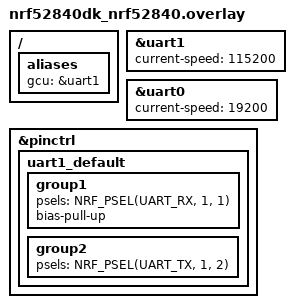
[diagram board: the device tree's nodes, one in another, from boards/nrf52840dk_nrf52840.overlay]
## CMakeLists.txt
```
# SPDX-License-Identifier: Apache-2.0

cmake_minimum_required(VERSION 3.20.0)
find_package(Zephyr REQUIRED HINTS $ENV{ZEPHYR_BASE})
project(prac2)

target_sources(app PRIVATE src/main.c)

zephyr_include_directories(../../include)

file(GLOB MYLIB_SOURCES ../../mylib/*.c)

foreach(mylib_src ${MYLIB_SOURCES})
    zephyr_library_sources(${mylib_src})
endforeach()
```

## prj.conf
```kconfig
CONFIG_GPIO=y
CONFIG_SERIAL=y
CONFIG_RING_BUFFER=y
CONFIG_PIPES=y
CONFIG_CBPRINTF_FP_SUPPORT=y
#CONFIG_PRINTK_BUFFER_SIZE=1 
#CONFIG_SHELL_STACK_SIZE=2048
CONFIG_UART_ASYNC_API=y

# get uart console on uart0 and async uart on uart1
CONFIG_UART_0_INTERRUPT_DRIVEN=n # Instance used by shell
CONFIG_UART_0_ASYNC=y
CONFIG_UART_0_NRF_HW_ASYNC=y
# enabling hw counting
CONFIG_UART_0_NRF_HW_ASYNC_TIMER=2
#CONFIG_UART_1_ASYNC=y
# instance for other purposes supporting async api
#CONFIG_UART_1_INTERRUPT_DRIVEN=n
#CONFIG_UART_1_NRF_HW_ASYNC=y
# enabling hw counting
#CONFIG_UART_1_NRF_HW_ASYNC_TIMER=2
# picking timer instance used for that

CONFIG_SYSTEM_WORKQUEUE_STACK_SIZE=2048

# Use the JSON library
CONFIG_JSON_LIBRARY=y


# RTT settings
CONFIG_SHELL_STACK_SIZE=1024
CONFIG_SHELL_BACKEND_SERIAL=n
CONFIG_SHELL_BACKEND_RTT=y
CONFIG_USE_SEGGER_RTT=y
```

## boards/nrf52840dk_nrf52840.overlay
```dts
/ {
    aliases {
        gcu = &uart1;
    };
};

&uart1 {
    status = "okay";
    current-speed = <115200>;
};

&uart0 {
    current-speed = <19200>;
};

&pinctrl {
	uart1_default: uart1_default {
		group1 {
			psels = <NRF_PSEL(UART_RX, 1, 1)>;
			bias-pull-up;
		};
		group2 {
			psels = <NRF_PSEL(UART_TX, 1, 2)>;
		};
	};
};
```

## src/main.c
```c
#include "async_uart.h"
#include "pc_json_requests.h"
#include <zephyr/logging/log.h>

LOG_MODULE_REGISTER(PRAC3_MAIN, LOG_LEVEL_DBG);

int main()
{
    // Initialise devices
    async_uart_init();
    for (;;) {
        k_msleep(1000);
        struct pedal_data data = {2323, -1204};
        send_pedal_json(data);
    }
}
```
